# SP28038 register map
Vendor: NXP Semiconductors; Series: SP2083X; File version: 1.0
CPU: CM4 r0p1, little endian, no MPU, FPU, VTOR, 4 interrupt priority bits
Registers are 32-bit, read-write, reset 0x0 unless marked. A register's access mark holds for its fields unless they carry their own. Offsets are from the block's base; [hi:lo] are bit positions; {n}, {i} and the like mark numbered series; 'fields as' and 'values as' point back to an identical list.

## ENET — Ethernet MAC-NET Core
Base 0x400C0000; register names take the prefix ENET_
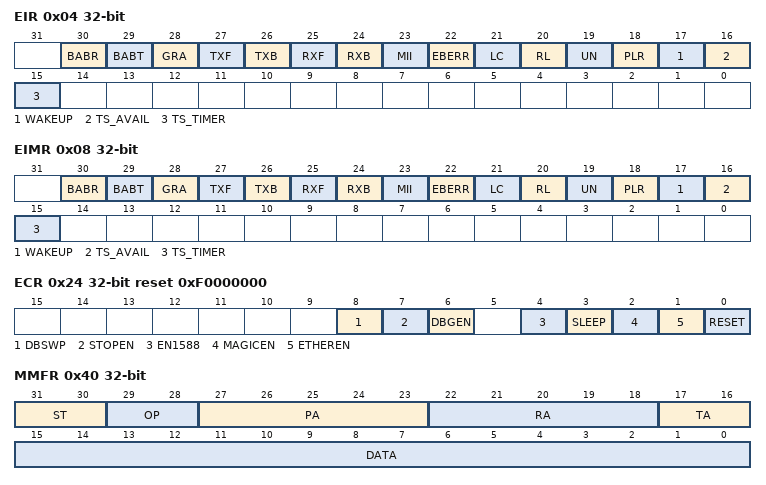
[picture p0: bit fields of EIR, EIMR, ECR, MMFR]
0x04 EIR — Interrupt Event Register
  [30] BABR — Babbling Receive Error
  [29] BABT — Babbling Transmit Error
  [28] GRA — Graceful Stop Complete
  [27] TXF — Transmit Frame Interrupt
  [26] TXB — Transmit Buffer Interrupt
  [25] RXF — Receive Frame Interrupt
  [24] RXB — Receive Buffer Interrupt
  [23] MII — MII Interrupt.
  [22] EBERR — Ethernet Bus Error
  [21] LC — Late Collision
  [20] RL — Collision Retry Limit
  [19] UN — Transmit FIFO Underrun
  [18] PLR — Payload Receive Error
  [17] WAKEUP — Node Wakeup Request Indication
  [16] TS_AVAIL — Transmit Timestamp Available
  [15] TS_TIMER — Timestamp Timer
0x08 EIMR — Interrupt Mask Register
  [30] BABR — BABR Interrupt Mask
    0=The corresponding interrupt source is masked; 1=The corresponding interrupt source is not masked
  [29] BABT — BABT Interrupt Mask
    values as BABR
  [28] GRA — GRA Interrupt Mask
    values as BABR
  [27] TXF — TXF Interrupt Mask
    values as BABR
  [26] TXB — TXB Interrupt Mask
    values as BABR
  [25] RXF — RXF Interrupt Mask
  [24] RXB — RXB Interrupt Mask
  [23] MII — MII Interrupt Mask
  [22] EBERR — EBERR Interrupt Mask
  [21] LC — LC Interrupt Mask
  [20] RL — RL Interrupt Mask
  [19] UN — UN Interrupt Mask
  [18] PLR — PLR Interrupt Mask
  [17] WAKEUP — WAKEUP Interrupt Mask
  [16] TS_AVAIL — TS_AVAIL Interrupt Mask
  [15] TS_TIMER — TS_TIMER Interrupt Mask
0x10 RDAR — Receive Descriptor Active Register
  [24] RDAR — Receive Descriptor Active
0x14 TDAR — Transmit Descriptor Active Register
  [24] TDAR — Transmit Descriptor Active
0x24 ECR reset 0xF0000000 — Ethernet Control Register
  [8] DBSWP — Descriptor Byte Swapping Enable
    0=The buffer descriptor bytes are not swapped to support big-endian devices; 1=The buffer descriptor bytes are swapped to support little-endian devices
  [7] STOPEN — STOPEN Signal Control
  [6] DBGEN — Debug Enable
    0=MAC continues operation in debug mode; 1=MAC enters hardware freeze mode when the processor is in debug mode
  [4] EN1588 — EN1588 Enable
    0=Legacy FEC buffer descriptors and functions enabled; 1=Enhanced frame time-stamping functions enabled
  [3] SLEEP — Sleep Mode Enable
    0=Normal operating mode; 1=Sleep mode
  [2] MAGICEN — Magic Packet Detection Enable
    0=Magic detection logic disabled; 1=The MAC core detects magic packets and asserts EIR[WAKEUP] when a frame is detected
  [1] ETHEREN — Ethernet Enable
    0=Reception immediately stops and transmission stops after a bad CRC is appended to any currently transmitted frame; 1=MAC is enabled, and reception and transmission are possible
  [0] RESET — Ethernet MAC Reset
0x40 MMFR — MII Management Frame Register
  [31:30] ST — Start Of Frame Delimiter
  [29:28] OP — Operation Code
  [27:23] PA — PHY Address
  [22:18] RA — Register Address
  [17:16] TA — Turn Around
  [15:0] DATA — Management Frame Data
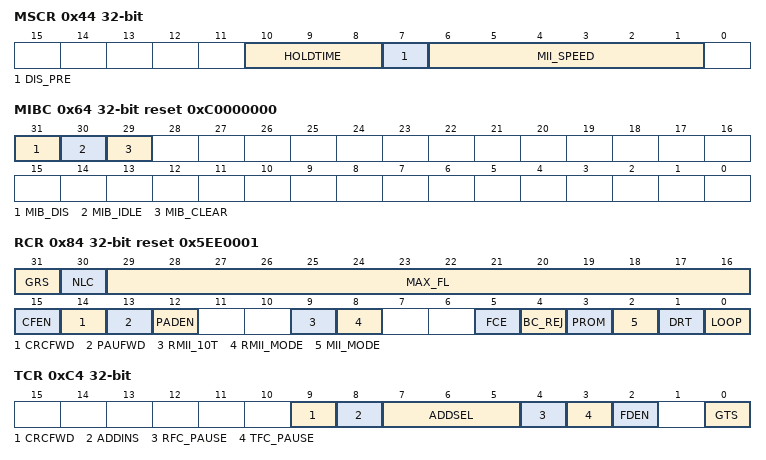
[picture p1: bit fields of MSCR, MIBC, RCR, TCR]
0x44 MSCR — MII Speed Control Register
  [10:8] HOLDTIME — Hold time On MDIO Output
    0=1 internal module clock cycle; 1=2 internal module clock cycles; 2=3 internal module clock cycles; 7=8 internal module clock cycles
  [7] DIS_PRE — Disable Preamble
    0=Preamble enabled; 1=Preamble (32 ones) is not prepended to the MII management frame
  [6:1] MII_SPEED
0x64 MIBC reset 0xC0000000 — MIB Control Register
  [31] MIB_DIS — Disable MIB Logic
    0=MIB logic is enabled; 1=MIB logic is disabled. The MIB logic halts and does not update any MIB counters.
  [30] MIB_IDLE ro
    0=The MIB block is updating MIB counters; 1=The MIB block is not currently updating any MIB counters
  [29] MIB_CLEAR
    0=See note above; 1=All statistics counters are reset to 0
0x84 RCR reset 0x5EE0001 — Receive Control Register
  [31] GRS ro — Graceful Receive Stopped
  [30] NLC — Payload Length Check Disable
    0=The payload length check is disabled; 1=The core checks the frame's payload length with the frame length/type field. Errors are indicated in the EIR[PLC] field.
  [29:16] MAX_FL — Maximum Frame Length
  [15] CFEN — MAC Control Frame Enable
    0=MAC control frames with any opcode other than 0x0001 (pause frame) are accepted and forwarded to the client interface; 1=MAC control frames with any opcode other than 0x0001 (pause frame) are silently discarded
  [14] CRCFWD — Terminate/Forward Received CRC
    0=The CRC field of received frames is transmitted to the user application; 1=The CRC field is stripped from the frame
  [13] PAUFWD — Terminate/Forward Pause Frames
    0=Pause frames are terminated and discarded in the MAC; 1=Pause frames are forwarded to the user application
  [12] PADEN — Enable Frame Padding Remove On Receive
    0=No padding is removed on receive by the MAC; 1=Padding is removed from received frames
  [9] RMII_10T — Enables 10-Mbps mode of the RMII .
    0=100 Mbps operation; 1=10 Mbps operation
  [8] RMII_MODE — RMII Mode Enable
    0=MAC configured for MII mode; 1=MAC configured for RMII operation
  [5] FCE — Flow Control Enable
  [4] BC_REJ — Broadcast Frame Reject
  [3] PROM — Promiscuous Mode
    0=Disabled; 1=Enabled
  [2] MII_MODE — Media Independent Interface Mode
    1=MII or RMII mode, as indicated by the RMII_MODE field
  [1] DRT — Disable Receive On Transmit
    0=Receive path operates independently of transmit. Used for full-duplex or to monitor transmit activity in half-duplex mode.; 1=Disable reception of frames while transmitting. Normally used for half-duplex mode.
  [0] LOOP — Internal Loopback
    0=Loopback disabled; 1=Transmitted frames are looped back internal to the device and transmit MII output signals are not asserted. DRT must be cleared.
0xC4 TCR — Transmit Control Register
  [9] CRCFWD — Forward Frame From Application With CRC
    0=TxBD[TC] controls whether the frame has a CRC from the application; 1=The transmitter does not append any CRC to transmitted frames, as it is expecting a frame with CRC from the application
  [8] ADDINS — Set MAC Address On Transmit
    0=The source MAC address is not modified by the MAC; 1=The MAC overwrites the source MAC address with the programmed MAC address according to ADDSEL
  [7:5] ADDSEL — Source MAC Address Select On Transmit
    0=Node MAC address programmed on PADDR1/2 registers
  [4] RFC_PAUSE ro — Receive Frame Control Pause
  [3] TFC_PAUSE — Transmit Frame Control Pause
    0=No PAUSE frame transmitted; 1=The MAC stops transmission of data frames after the current transmission is complete
  [2] FDEN — Full-Duplex Enable
  [0] GTS — Graceful Transmit Stop
0xE4 PALR — Physical Address Lower Register
  [31:0] PADDR1 — Pause Address
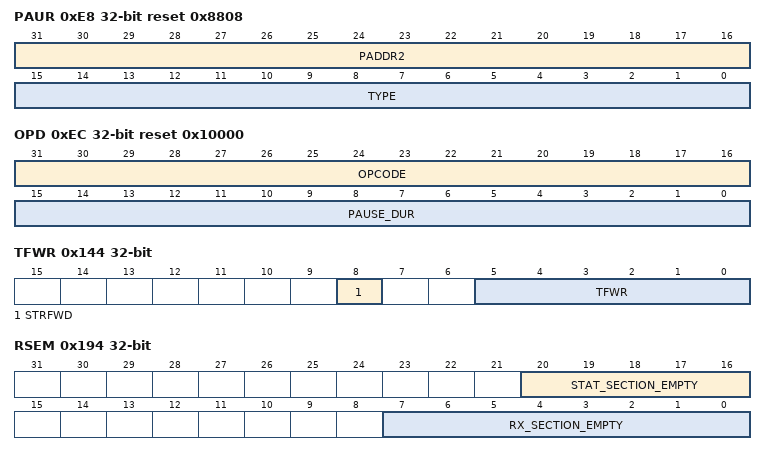
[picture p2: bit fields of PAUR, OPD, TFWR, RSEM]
0xE8 PAUR reset 0x8808 — Physical Address Upper Register
  [31:16] PADDR2 — Bytes 4 (bits 31:24) and 5 (bits 23:16) of the 6-byte individual address used for exact match, and the source address field in PAUSE frames
  [15:0] TYPE ro — Type Field In PAUSE Frames
0xEC OPD reset 0x10000 — Opcode/Pause Duration Register
  [31:16] OPCODE ro — Opcode Field In PAUSE Frames
  [15:0] PAUSE_DUR — Pause Duration
0x118 IAUR — Descriptor Individual Upper Address Register
  [31:0] IADDR1 — Contains the upper 32 bits of the 64-bit hash table used in the address recognition process for receive frames with a unicast address
0x11C IALR — Descriptor Individual Lower Address Register
  [31:0] IADDR2 — Contains the lower 32 bits of the 64-bit hash table used in the address recognition process for receive frames with a unicast address
0x120 GAUR — Descriptor Group Upper Address Register
  [31:0] GADDR1 — Contains the upper 32 bits of the 64-bit hash table used in the address recognition process for receive frames with a multicast address
0x124 GALR — Descriptor Group Lower Address Register
  [31:0] GADDR2 — Contains the lower 32 bits of the 64-bit hash table used in the address recognition process for receive frames with a multicast address
0x144 TFWR — Transmit FIFO Watermark Register
  [8] STRFWD — Store And Forward Enable
    0=Reset. The transmission start threshold is programmed in TFWR[TFWR].; 1=Enabled
  [5:0] TFWR — Transmit FIFO Write
    0=64 bytes written; 1=64 bytes written; 2=128 bytes written; 3=192 bytes written; 31=1984 bytes written
0x180 RDSR — Receive Descriptor Ring Start Register
  [31:3] R_DES_START — Pointer to the beginning of the receive buffer descriptor queue.
0x184 TDSR — Transmit Buffer Descriptor Ring Start Register
  [31:3] X_DES_START — Pointer to the beginning of the transmit buffer descriptor queue.
0x188 MRBR — Maximum Receive Buffer Size Register
  [10:4] R_BUF_SIZE — Receive buffer size in bytes
0x190 RSFL — Receive FIFO Section Full Threshold
  [7:0] RX_SECTION_FULL — Value Of Receive FIFO Section Full Threshold
0x194 RSEM — Receive FIFO Section Empty Threshold
  [20:16] STAT_SECTION_EMPTY — RX Status FIFO Section Empty Threshold
  [7:0] RX_SECTION_EMPTY — Value Of The Receive FIFO Section Empty Threshold
0x198 RAEM reset 0x4 — Receive FIFO Almost Empty Threshold
  [7:0] RX_ALMOST_EMPTY — Value Of The Receive FIFO Almost Empty Threshold
0x19C RAFL reset 0x4 — Receive FIFO Almost Full Threshold
  [7:0] RX_ALMOST_FULL — Value Of The Receive FIFO Almost Full Threshold
0x1A0 TSEM — Transmit FIFO Section Empty Threshold
  [7:0] TX_SECTION_EMPTY — Value Of The Transmit FIFO Section Empty Threshold
0x1A4 TAEM reset 0x4 — Transmit FIFO Almost Empty Threshold
  [7:0] TX_ALMOST_EMPTY — Value of Transmit FIFO Almost Empty Threshold
0x1A8 TAFL reset 0x8 — Transmit FIFO Almost Full Threshold
  [7:0] TX_ALMOST_FULL — Value Of The Transmit FIFO Almost Full Threshold
0x1AC TIPG reset 0xC — Transmit Inter-Packet Gap
  [4:0] IPG
0x1B0 FTRL reset 0x7FF — Frame Truncation Length
  [13:0] TRUNC_FL
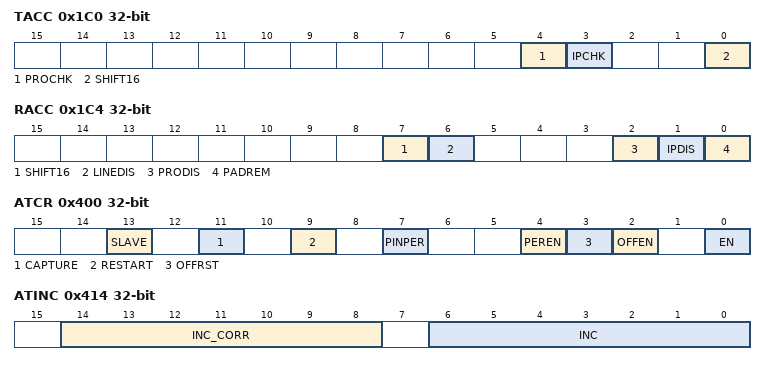
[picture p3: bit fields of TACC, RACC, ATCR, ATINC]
0x1C0 TACC — Transmit Accelerator Function Configuration
  [4] PROCHK — Enables insertion of protocol checksum.
    0=Checksum not inserted; 1=If an IP frame with a known protocol is transmitted, the checksum is inserted automatically into the frame. The checksum field must be cleared. The other frames are not modified.
  [3] IPCHK — Enables insertion of IP header checksum.
    0=Checksum is not inserted; 1=If an IP frame is transmitted, the checksum is inserted automatically. The IP header checksum field must be cleared. If a non-IP frame is transmitted the frame is not modified.
  [0] SHIFT16 — TX FIFO Shift-16
    0=Disabled; 1=Indicates to the transmit data FIFO that the written frames contain two additional octets before the frame data. This means the actual frame begins at bit 16 of the first word written into the FIFO. This function allows putting the frame payload on a 32-bit boundary in memory, as the 14-byte Ethernet header is extended to a 16-byte header.
0x1C4 RACC — Receive Accelerator Function Configuration
  [7] SHIFT16 — RX FIFO Shift-16
    0=Disabled; 1=Instructs the MAC to write two additional bytes in front of each frame received into the RX FIFO
  [6] LINEDIS — Enable Discard Of Frames With MAC Layer Errors
    0=Frames with errors are not discarded; 1=Any frame received with a CRC, length, or PHY error is automatically discarded and not forwarded to the user application interface
  [2] PRODIS — Enable Discard Of Frames With Wrong Protocol Checksum
    0=Frames with wrong checksum are not discarded; 1=If a TCP/IP, UDP/IP, or ICMP/IP frame is received that has a wrong TCP, UDP, or ICMP checksum, the frame is discarded. Discarding is only available when the RX FIFO operates in store and forward mode (RSFL cleared).
  [1] IPDIS — Enable Discard Of Frames With Wrong IPv4 Header Checksum
    0=Frames with wrong IPv4 header checksum are not discarded; 1=If an IPv4 frame is received with a mismatching header checksum, the frame is discarded. IPv6 has no header checksum and is not affected by this setting. Discarding is only available when the RX FIFO operates in store and forward mode (RSFL cleared).
  [0] PADREM — Enable Padding Removal For Short IP Frames
    0=Padding not removed; 1=Any bytes following the IP payload section of the frame are removed from the frame
0x200 RMON_T_DROP ro — Reserved Statistic Register
0x204 RMON_T_PACKETS ro — Tx Packet Count Statistic Register
  [15:0] TXPKTS — Packet count
0x208 RMON_T_BC_PKT ro — Tx Broadcast Packets Statistic Register
  [15:0] TXPKTS — Broadcast packets
0x20C RMON_T_MC_PKT ro — Tx Multicast Packets Statistic Register
  [15:0] TXPKTS — Multicast packets
0x210 RMON_T_CRC_ALIGN ro — Tx Packets with CRC/Align Error Statistic Register
  [15:0] TXPKTS — Packets with CRC/align error
0x214 RMON_T_UNDERSIZE ro — Tx Packets Less Than Bytes and Good CRC Statistic Register
  [15:0] TXPKTS — Number of transmit packets less than 64 bytes with good CRC
0x218 RMON_T_OVERSIZE ro — Tx Packets GT MAX_FL bytes and Good CRC Statistic Register
  [15:0] TXPKTS — Number of transmit packets greater than MAX_FL bytes with good CRC
0x21C RMON_T_FRAG ro — Tx Packets Less Than 64 Bytes and Bad CRC Statistic Register
  [15:0] TXPKTS — Number of packets less than 64 bytes with bad CRC
0x220 RMON_T_JAB ro — Tx Packets Greater Than MAX_FL bytes and Bad CRC Statistic Register
  [15:0] TXPKTS — Number of transmit packets greater than MAX_FL bytes and bad CRC
0x224 RMON_T_COL ro — Tx Collision Count Statistic Register
  [15:0] TXPKTS — Number of transmit collisions
0x228 RMON_T_P64 ro — Tx 64-Byte Packets Statistic Register
  [15:0] TXPKTS — Number of 64-byte transmit packets
0x22C RMON_T_P65TO127 ro — Tx 65- to 127-byte Packets Statistic Register
  [15:0] TXPKTS — Number of 65- to 127-byte transmit packets
0x230 RMON_T_P128TO255 ro — Tx 128- to 255-byte Packets Statistic Register
  [15:0] TXPKTS — Number of 128- to 255-byte transmit packets
0x234 RMON_T_P256TO511 ro — Tx 256- to 511-byte Packets Statistic Register
  [15:0] TXPKTS — Number of 256- to 511-byte transmit packets
0x238 RMON_T_P512TO1023 ro — Tx 512- to 1023-byte Packets Statistic Register
  [15:0] TXPKTS — Number of 512- to 1023-byte transmit packets
0x23C RMON_T_P1024TO2047 ro — Tx 1024- to 2047-byte Packets Statistic Register
  [15:0] TXPKTS — Number of 1024- to 2047-byte transmit packets
0x240 RMON_T_P_GTE2048 ro — Tx Packets Greater Than 2048 Bytes Statistic Register
  [15:0] TXPKTS — Number of transmit packets greater than 2048 bytes
0x244 RMON_T_OCTETS ro — Tx Octets Statistic Register
  [31:0] TXOCTS — Number of transmit octets
0x248 IEEE_T_DROP ro — IEEE_T_DROP Reserved Statistic Register
0x24C IEEE_T_FRAME_OK ro — Frames Transmitted OK Statistic Register
  [15:0] COUNT — Number of frames transmitted OK
0x250 IEEE_T_1COL ro — Frames Transmitted with Single Collision Statistic Register
  [15:0] COUNT — Number of frames transmitted with one collision
0x254 IEEE_T_MCOL ro — Frames Transmitted with Multiple Collisions Statistic Register
  [15:0] COUNT — Number of frames transmitted with multiple collisions
0x258 IEEE_T_DEF ro — Frames Transmitted after Deferral Delay Statistic Register
  [15:0] COUNT — Number of frames transmitted with deferral delay
0x25C IEEE_T_LCOL ro — Frames Transmitted with Late Collision Statistic Register
  [15:0] COUNT — Number of frames transmitted with late collision
0x260 IEEE_T_EXCOL ro — Frames Transmitted with Excessive Collisions Statistic Register
  [15:0] COUNT — Number of frames transmitted with excessive collisions
0x264 IEEE_T_MACERR ro — Frames Transmitted with Tx FIFO Underrun Statistic Register
  [15:0] COUNT — Number of frames transmitted with transmit FIFO underrun
0x268 IEEE_T_CSERR ro — Frames Transmitted with Carrier Sense Error Statistic Register
  [15:0] COUNT — Number of frames transmitted with carrier sense error
0x26C IEEE_T_SQE ro
  [15:0] COUNT — Number of frames transmitted with SQE error
0x270 IEEE_T_FDXFC ro — Flow Control Pause Frames Transmitted Statistic Register
  [15:0] COUNT — Number of flow-control pause frames transmitted
0x274 IEEE_T_OCTETS_OK ro — Octet Count for Frames Transmitted w/o Error Statistic Register
  [31:0] COUNT — Octet count for frames transmitted without error Counts total octets (includes header and FCS fields).
0x284 RMON_R_PACKETS ro — Rx Packet Count Statistic Register
  [15:0] COUNT — Number of packets received
0x288 RMON_R_BC_PKT ro — Rx Broadcast Packets Statistic Register
  [15:0] COUNT — Number of receive broadcast packets
0x28C RMON_R_MC_PKT ro — Rx Multicast Packets Statistic Register
  [15:0] COUNT — Number of receive multicast packets
0x290 RMON_R_CRC_ALIGN ro — Rx Packets with CRC/Align Error Statistic Register
  [15:0] COUNT — Number of receive packets with CRC or align error
0x294 RMON_R_UNDERSIZE ro — Rx Packets with Less Than 64 Bytes and Good CRC Statistic Register
  [15:0] COUNT — Number of receive packets with less than 64 bytes and good CRC
0x298 RMON_R_OVERSIZE ro — Rx Packets Greater Than MAX_FL and Good CRC Statistic Register
  [15:0] COUNT — Number of receive packets greater than MAX_FL and good CRC
0x29C RMON_R_FRAG ro — Rx Packets Less Than 64 Bytes and Bad CRC Statistic Register
  [15:0] COUNT — Number of receive packets with less than 64 bytes and bad CRC
0x2A0 RMON_R_JAB ro — Rx Packets Greater Than MAX_FL Bytes and Bad CRC Statistic Register
  [15:0] COUNT — Number of receive packets greater than MAX_FL and bad CRC
0x2A4 RMON_R_RESVD_0 ro — Reserved Statistic Register
0x2A8 RMON_R_P64 ro — Rx 64-Byte Packets Statistic Register
  [15:0] COUNT — Number of 64-byte receive packets
0x2AC RMON_R_P65TO127 ro — Rx 65- to 127-Byte Packets Statistic Register
  [15:0] COUNT — Number of 65- to 127-byte recieve packets
0x2B0 RMON_R_P128TO255 ro — Rx 128- to 255-Byte Packets Statistic Register
  [15:0] COUNT — Number of 128- to 255-byte recieve packets
0x2B4 RMON_R_P256TO511 ro — Rx 256- to 511-Byte Packets Statistic Register
  [15:0] COUNT — Number of 256- to 511-byte recieve packets
0x2B8 RMON_R_P512TO1023 ro — Rx 512- to 1023-Byte Packets Statistic Register
  [15:0] COUNT — Number of 512- to 1023-byte recieve packets
0x2BC RMON_R_P1024TO2047 ro — Rx 1024- to 2047-Byte Packets Statistic Register
  [15:0] COUNT — Number of 1024- to 2047-byte recieve packets
0x2C0 RMON_R_P_GTE2048 ro — Rx Packets Greater than 2048 Bytes Statistic Register
  [15:0] COUNT — Number of greater-than-2048-byte recieve packets
0x2C4 RMON_R_OCTETS ro — Rx Octets Statistic Register
  [31:0] COUNT — Number of receive octets
0x2C8 IEEE_R_DROP ro — Frames not Counted Correctly Statistic Register
  [15:0] COUNT — Frame count
0x2CC IEEE_R_FRAME_OK ro — Frames Received OK Statistic Register
  [15:0] COUNT — Number of frames received OK
0x2D0 IEEE_R_CRC ro — Frames Received with CRC Error Statistic Register
  [15:0] COUNT — Number of frames received with CRC error
0x2D4 IEEE_R_ALIGN ro — Frames Received with Alignment Error Statistic Register
  [15:0] COUNT — Number of frames received with alignment error
0x2D8 IEEE_R_MACERR ro — Receive FIFO Overflow Count Statistic Register
  [15:0] COUNT — Receive FIFO overflow count
0x2DC IEEE_R_FDXFC ro — Flow Control Pause Frames Received Statistic Register
  [15:0] COUNT — Number of flow-control pause frames received
0x2E0 IEEE_R_OCTETS_OK ro — Octet Count for Frames Received without Error Statistic Register
  [31:0] COUNT — Number of octets for frames received without error
0x400 ATCR — Adjustable Timer Control Register
  [13] SLAVE — Enable Timer Slave Mode
    0=The timer is active and all configuration fields in this register are relevant; 1=The internal timer is disabled and the externally provided timer value is used. All other fields, except CAPTURE, in this register have no effect. CAPTURE can still be used to capture the current timer value.
  [11] CAPTURE — Capture Timer Value
    0=No effect; 1=The current time is captured and can be read from the ATVR register
  [9] RESTART — Reset Timer
  [7] PINPER — Enables event signal output assertion on period event
    0=Disable; 1=Enable
  [4] PEREN — Enable Periodical Event
    0=Disable; 1=A period event interrupt can be generated (EIR[TS_TIMER]) and the event signal output is asserted when the timer wraps around according to the periodic setting ATPER. The timer period value must be set before setting this bit. Not all devices contain the event signal output. See the chip configuration details.
  [3] OFFRST — Reset Timer On Offset Event
    0=The timer is not affected and no action occurs, besides clearing OFFEN, when the offset is reached; 1=If OFFEN is set, the timer resets to zero when the offset setting is reached. The offset event does not cause a timer interrupt.
  [2] OFFEN — Enable One-Shot Offset Event
    0=Disable; 1=The timer can be reset to zero when the given offset time is reached (offset event). The field is cleared when the offset event is reached, so no further event occurs until the field is set again. The timer offset value must be set before setting this field.
  [0] EN — Enable Timer
    0=The timer stops at the current value; 1=The timer starts incrementing
0x404 ATVR — Timer Value Register
  [31:0] ATIME — A write sets the timer
0x408 ATOFF — Timer Offset Register
  [31:0] OFFSET — Offset value for one-shot event generation
0x40C ATPER reset 0x3B9ACA00 — Timer Period Register
  [31:0] PERIOD — Value for generating periodic events
0x410 ATCOR — Timer Correction Register
  [30:0] COR — Correction Counter Wrap-Around Value
0x414 ATINC — Time-Stamping Clock Period Register
  [14:8] INC_CORR — Correction Increment Value
  [6:0] INC — Clock Period Of The Timestamping Clock (ts_clk) In Nanoseconds
0x418 ATSTMP ro — Timestamp of Last Transmitted Frame
  [31:0] TIMESTAMP — Timestamp of the last frame transmitted by the core that had TxBD[TS] set
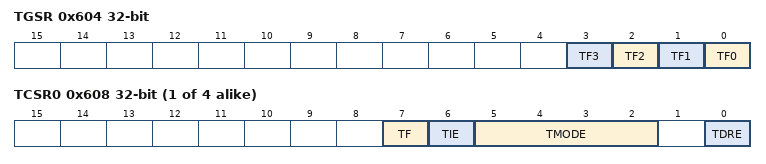
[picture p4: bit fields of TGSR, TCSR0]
0x604 TGSR — Timer Global Status Register
  [n] TF{n} (n=0..3) — Copy Of Timer Flag For Channel {n}
    0=Timer Flag for Channel {n} is clear; 1=Timer Flag for Channel {n} is set
{0x608+8i} TCSR{i} (i=0..3) — Timer Control Status Register
  [7] TF — Timer Flag
    0=Input Capture or Output Compare has not occurred; 1=Input Capture or Output Compare has occurred
  [6] TIE — Timer Interrupt Enable
    0=Interrupt is disabled; 1=Interrupt is enabled
  [5:2] TMODE — Timer Mode
    0=Timer Channel is disabled; 1=Timer Channel is configured for Input Capture on rising edge; 2=Timer Channel is configured for Input Capture on falling edge; 3=Timer Channel is configured for Input Capture on both edges; 4=Timer Channel is configured for Output Compare - software only; 5=Timer Channel is configured for Output Compare - toggle output on compare; 6=Timer Channel is configured for Output Compare - clear output on compare; 7=Timer Channel is configured for Output Compare - set output on compare; 10=Timer Channel is configured for Output Compare - clear output on compare, set output on overflow; 14=Timer Channel is configured for Output Compare - pulse output low on compare for one 1588-clock cycle; 15=Timer Channel is configured for Output Compare - pulse output high on compare for one 1588-clock cycle
  [0] TDRE — Timer DMA Request Enable
    0=DMA request is disabled; 1=DMA request is enabled
{0x60C+8i} TCCR{i} (i=0..3) — Timer Compare Capture Register
  [31:0] TCC — Timer Capture Compare
